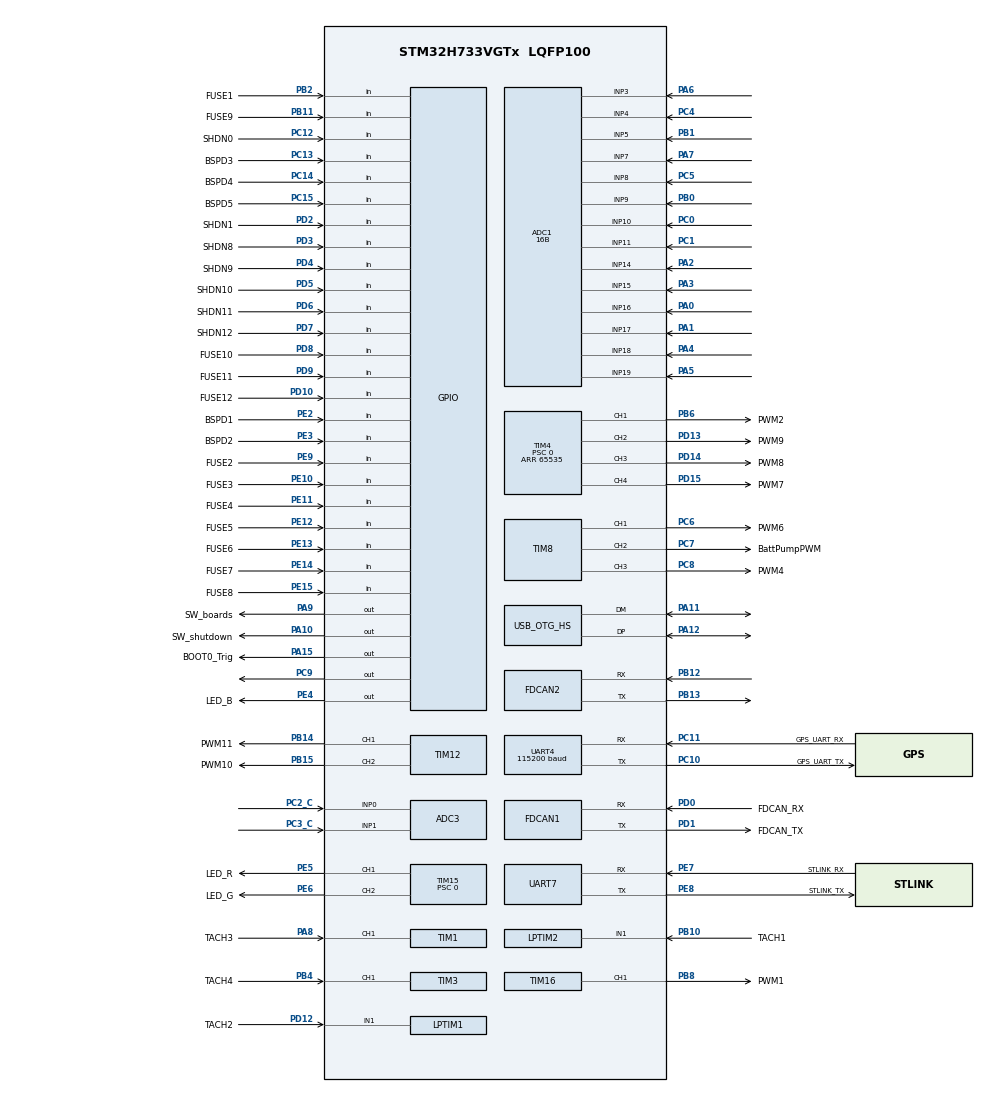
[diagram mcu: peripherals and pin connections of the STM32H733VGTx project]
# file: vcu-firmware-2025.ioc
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ADC1.Channel-1\#ChannelRegularConversion=ADC_CHANNEL_3
ADC1.Channel-10\#ChannelRegularConversion=ADC_CHANNEL_15
ADC1.Channel-11\#ChannelRegularConversion=ADC_CHANNEL_16
ADC1.Channel-12\#ChannelRegularConversion=ADC_CHANNEL_17
ADC1.Channel-13\#ChannelRegularConversion=ADC_CHANNEL_18
ADC1.Channel-14\#ChannelRegularConversion=ADC_CHANNEL_19
ADC1.Channel-2\#ChannelRegularConversion=ADC_CHANNEL_4
ADC1.Channel-3\#ChannelRegularConversion=ADC_CHANNEL_5
ADC1.Channel-4\#ChannelRegularConversion=ADC_CHANNEL_7
ADC1.Channel-5\#ChannelRegularConversion=ADC_CHANNEL_8
ADC1.Channel-6\#ChannelRegularConversion=ADC_CHANNEL_9
ADC1.Channel-7\#ChannelRegularConversion=ADC_CHANNEL_10
ADC1.Channel-8\#ChannelRegularConversion=ADC_CHANNEL_11
ADC1.Channel-9\#ChannelRegularConversion=ADC_CHANNEL_14
ADC1.ClockPrescaler=ADC_CLOCK_ASYNC_DIV64
ADC1.ContinuousConvMode=ENABLE
ADC1.ConversionDataManagement=ADC_CONVERSIONDATA_DMA_CIRCULAR
ADC1.EOCSelection=ADC_EOC_SEQ_CONV
ADC1.EnableRegularConversion=ENABLE
ADC1.NbrOfConversion=14
ADC1.NbrOfConversionFlag=1
ADC1.OffsetNumber-1\#ChannelRegularConversion=ADC_OFFSET_NONE
ADC1.OffsetNumber-10\#ChannelRegularConversion=ADC_OFFSET_NONE
ADC1.OffsetNumber-11\#ChannelRegularConversion=ADC_OFFSET_NONE
ADC1.OffsetNumber-12\#ChannelRegularConversion=ADC_OFFSET_NONE
ADC1.OffsetNumber-13\#ChannelRegularConversion=ADC_OFFSET_NONE
ADC1.OffsetNumber-14\#ChannelRegularConversion=ADC_OFFSET_NONE
ADC1.OffsetNumber-2\#ChannelRegularConversion=ADC_OFFSET_NONE
ADC1.OffsetNumber-3\#ChannelRegularConversion=ADC_OFFSET_NONE
ADC1.OffsetNumber-4\#ChannelRegularConversion=ADC_OFFSET_NONE
ADC1.OffsetNumber-5\#ChannelRegularConversion=ADC_OFFSET_NONE
ADC1.OffsetNumber-6\#ChannelRegularConversion=ADC_OFFSET_NONE
ADC1.OffsetNumber-7\#ChannelRegularConversion=ADC_OFFSET_NONE
ADC1.OffsetNumber-8\#ChannelRegularConversion=ADC_OFFSET_NONE
ADC1.OffsetNumber-9\#ChannelRegularConversion=ADC_OFFSET_NONE
ADC1.OffsetSignedSaturation-1\#ChannelRegularConversion=DISABLE
ADC1.OffsetSignedSaturation-10\#ChannelRegularConversion=DISABLE
ADC1.OffsetSignedSaturation-11\#ChannelRegularConversion=DISABLE
ADC1.OffsetSignedSaturation-12\#ChannelRegularConversion=DISABLE
ADC1.OffsetSignedSaturation-13\#ChannelRegularConversion=DISABLE
ADC1.OffsetSignedSaturation-14\#ChannelRegularConversion=DISABLE
ADC1.OffsetSignedSaturation-2\#ChannelRegularConversion=DISABLE
ADC1.OffsetSignedSaturation-3\#ChannelRegularConversion=DISABLE
ADC1.OffsetSignedSaturation-4\#ChannelRegularConversion=DISABLE
ADC1.OffsetSignedSaturation-5\#ChannelRegularConversion=DISABLE
ADC1.OffsetSignedSaturation-6\#ChannelRegularConversion=DISABLE
ADC1.OffsetSignedSaturation-7\#ChannelRegularConversion=DISABLE
ADC1.OffsetSignedSaturation-8\#ChannelRegularConversion=DISABLE
ADC1.OffsetSignedSaturation-9\#ChannelRegularConversion=DISABLE
ADC1.OversamplingMode=ENABLE
ADC1.Rank-1\#ChannelRegularConversion=1
ADC1.Rank-10\#ChannelRegularConversion=10
ADC1.Rank-11\#ChannelRegularConversion=11
ADC1.Rank-12\#ChannelRegularConversion=12
ADC1.Rank-13\#ChannelRegularConversion=13
ADC1.Rank-14\#ChannelRegularConversion=14
ADC1.Rank-2\#ChannelRegularConversion=2
ADC1.Rank-3\#ChannelRegularConversion=3
ADC1.Rank-4\#ChannelRegularConversion=4
ADC1.Rank-5\#ChannelRegularConversion=5
ADC1.Rank-6\#ChannelRegularConversion=6
ADC1.Rank-7\#ChannelRegularConversion=7
ADC1.Rank-8\#ChannelRegularConversion=8
ADC1.Rank-9\#ChannelRegularConversion=9
ADC1.Ratio=16
ADC1.Resolution=ADC_RESOLUTION_16B
ADC1.RightBitShift=ADC_RIGHTBITSHIFT_4
ADC1.SamplingTime-1\#ChannelRegularConversion=ADC_SAMPLETIME_1CYCLE_5
ADC1.SamplingTime-10\#ChannelRegularConversion=ADC_SAMPLETIME_1CYCLE_5
ADC1.SamplingTime-11\#ChannelRegularConversion=ADC_SAMPLETIME_1CYCLE_5
ADC1.SamplingTime-12\#ChannelRegularConversion=ADC_SAMPLETIME_1CYCLE_5
ADC1.SamplingTime-13\#ChannelRegularConversion=ADC_SAMPLETIME_1CYCLE_5
ADC1.SamplingTime-14\#ChannelRegularConversion=ADC_SAMPLETIME_1CYCLE_5
ADC1.SamplingTime-2\#ChannelRegularConversion=ADC_SAMPLETIME_1CYCLE_5
ADC1.SamplingTime-3\#ChannelRegularConversion=ADC_SAMPLETIME_1CYCLE_5
ADC1.SamplingTime-4\#ChannelRegularConversion=ADC_SAMPLETIME_1CYCLE_5
ADC1.SamplingTime-5\#ChannelRegularConversion=ADC_SAMPLETIME_1CYCLE_5
ADC1.SamplingTime-6\#ChannelRegularConversion=ADC_SAMPLETIME_1CYCLE_5
ADC1.SamplingTime-7\#ChannelRegularConversion=ADC_SAMPLETIME_1CYCLE_5
ADC1.SamplingTime-8\#ChannelRegularConversion=ADC_SAMPLETIME_1CYCLE_5
ADC1.SamplingTime-9\#ChannelRegularConversion=ADC_SAMPLETIME_1CYCLE_5
ADC1.master=1
ADC3.Channel-1\#ChannelRegularConversion=ADC_CHANNEL_0
ADC3.Channel-2\#ChannelRegularConversion=ADC_CHANNEL_1
ADC3.ClockPrescaler=ADC_CLOCK_ASYNC_DIV64
ADC3.ContinuousConvMode=ENABLE
ADC3.ConversionDataManagement=ADC_CONVERSIONDATA_DMA_CIRCULAR
ADC3.DMAContinuousRequests=DISABLE
ADC3.EOCSelection=ADC_EOC_SEQ_CONV
ADC3.NbrOfConversion=2
ADC3.NbrOfConversionFlag=1
ADC3.OffsetNumber-1\#ChannelRegularConversion=ADC_OFFSET_NONE
ADC3.OffsetNumber-2\#ChannelRegularConversion=ADC_OFFSET_NONE
ADC3.OffsetSign-1\#ChannelRegularConversion=ADC3_OFFSET_SIGN_NEGATIVE
ADC3.OffsetSign-2\#ChannelRegularConversion=ADC3_OFFSET_SIGN_NEGATIVE
ADC3.Rank-1\#ChannelRegularConversion=1
ADC3.Rank-2\#ChannelRegularConversion=2
ADC3.ResolutionADC3=ADC_RESOLUTION_8B
ADC3.SamplingTime-1\#ChannelRegularConversion=ADC3_SAMPLETIME_2CYCLES_5
ADC3.SamplingTime-2\#ChannelRegularConversion=ADC3_SAMPLETIME_2CYCLES_5
CORTEX_M7.default_mode_Activation=1
Dma.ADC1.0.Direction=DMA_PERIPH_TO_MEMORY
Dma.ADC1.0.EventEnable=DISABLE
Dma.ADC1.0.FIFOMode=DMA_FIFOMODE_DISABLE
Dma.ADC1.0.Instance=DMA1_Stream2
Dma.ADC1.0.MemDataAlignment=DMA_MDATAALIGN_HALFWORD
Dma.ADC1.0.MemInc=DMA_MINC_ENABLE
Dma.ADC1.0.Mode=DMA_CIRCULAR
Dma.ADC1.0.PeriphDataAlignment=DMA_PDATAALIGN_HALFWORD
Dma.ADC1.0.PeriphInc=DMA_PINC_DISABLE
Dma.ADC1.0.Polarity=HAL_DMAMUX_REQ_GEN_RISING
Dma.ADC1.0.Priority=DMA_PRIORITY_LOW
Dma.ADC1.0.RequestNumber=1
Dma.ADC1.0.SignalID=NONE
Dma.ADC1.0.SyncEnable=DISABLE
Dma.ADC1.0.SyncPolarity=HAL_DMAMUX_SYNC_NO_EVENT
Dma.ADC1.0.SyncRequestNumber=1
Dma.ADC1.0.SyncSignalID=NONE
Dma.ADC3.1.Direction=DMA_PERIPH_TO_MEMORY
Dma.ADC3.1.EventEnable=DISABLE
Dma.ADC3.1.FIFOMode=DMA_FIFOMODE_DISABLE
Dma.ADC3.1.Instance=DMA1_Stream1
Dma.ADC3.1.MemDataAlignment=DMA_MDATAALIGN_BYTE
Dma.ADC3.1.MemInc=DMA_MINC_ENABLE
Dma.ADC3.1.Mode=DMA_CIRCULAR
Dma.ADC3.1.PeriphDataAlignment=DMA_PDATAALIGN_BYTE
Dma.ADC3.1.PeriphInc=DMA_PINC_DISABLE
Dma.ADC3.1.Polarity=HAL_DMAMUX_REQ_GEN_RISING
Dma.ADC3.1.Priority=DMA_PRIORITY_HIGH
Dma.ADC3.1.RequestNumber=1
Dma.ADC3.1.SignalID=NONE
Dma.ADC3.1.SyncEnable=DISABLE
Dma.ADC3.1.SyncPolarity=HAL_DMAMUX_SYNC_NO_EVENT
Dma.ADC3.1.SyncRequestNumber=1
Dma.ADC3.1.SyncSignalID=NONE
Dma.Request0=ADC1
Dma.Request1=ADC3
Dma.Request2=UART4_RX
Dma.UART4_RX.2.Direction=DMA_PERIPH_TO_MEMORY
Dma.UART4_RX.2.EventEnable=DISABLE
Dma.UART4_RX.2.FIFOMode=DMA_FIFOMODE_DISABLE
Dma.UART4_RX.2.Instance=DMA2_Stream0
Dma.UART4_RX.2.MemDataAlignment=DMA_MDATAALIGN_BYTE
Dma.UART4_RX.2.MemInc=DMA_MINC_ENABLE
Dma.UART4_RX.2.Mode=DMA_CIRCULAR
Dma.UART4_RX.2.PeriphDataAlignment=DMA_PDATAALIGN_BYTE
Dma.UART4_RX.2.PeriphInc=DMA_PINC_DISABLE
Dma.UART4_RX.2.Polarity=HAL_DMAMUX_REQ_GEN_RISING
Dma.UART4_RX.2.Priority=DMA_PRIORITY_HIGH
Dma.UART4_RX.2.RequestNumber=1
Dma.UART4_RX.2.SignalID=NONE
Dma.UART4_RX.2.SyncEnable=DISABLE
Dma.UART4_RX.2.SyncPolarity=HAL_DMAMUX_SYNC_NO_EVENT
Dma.UART4_RX.2.SyncRequestNumber=1
Dma.UART4_RX.2.SyncSignalID=NONE
FDCAN1.CalculateBaudRateNominal=1000000
FDCAN1.CalculateTimeBitNominal=1000
FDCAN1.CalculateTimeQuantumNominal=100.0
FDCAN1.NominalPrescaler=1
FDCAN1.NominalTimeSeg1=7
FDCAN1.RxFifo0ElmtsNbr=32
FDCAN1.RxFifo1ElmtsNbr=32
FDCAN1.TxFifoQueueElmtsNbr=32
FDCAN2.CalculateBaudRateNominal=500000
FDCAN2.CalculateTimeBitNominal=2000
FDCAN2.CalculateTimeQuantumNominal=400.0
FDCAN2.ClockCalibrationCCU=DISABLE
FDCAN2.NominalPrescaler=4
Mcu.Family=STM32H7
Mcu.Name=STM32H733VGTx
Mcu.Package=LQFP100
NVIC.DMA1_Stream1_IRQn=true\:0\:0\:false\:false\:true\:false\:true\:true
NVIC.DMA1_Stream2_IRQn=true\:0\:0\:false\:false\:true\:false\:true\:true
NVIC.DMA2_Stream0_IRQn=true\:0\:0\:false\:false\:true\:false\:true\:true
NVIC.OTG_HS_IRQn=true\:0\:0\:false\:false\:true\:false\:true\:true
NVIC.PriorityGroup=NVIC_PRIORITYGROUP_4
PA0.Mode=IN16-Single-Ended
PA0.Signal=ADC1_INP16
PA1.Mode=IN17-Single-Ended
PA1.Signal=ADC1_INP17
PA10.GPIO_Label=SW_shutdown
PA10.Signal=GPIO_Output
PA11.Mode=Device_Only_FS
PA11.Signal=USB_OTG_HS_DM
PA12.Mode=Device_Only_FS
PA12.Signal=USB_OTG_HS_DP
PA13(JTMS/SWDIO).Mode=Trace_Asynchronous_SW
PA13(JTMS/SWDIO).Signal=DEBUG_JTMS-SWDIO
PA14(JTCK/SWCLK).Mode=Trace_Asynchronous_SW
PA14(JTCK/SWCLK).Signal=DEBUG_JTCK-SWCLK
PA15(JTDI).GPIO_Label=BOOT0_Trig
PA15(JTDI).GPIO_PuPd=GPIO_PULLDOWN
PA15(JTDI).PinState=GPIO_PIN_RESET
PA15(JTDI).Signal=GPIO_Output
PA2.Signal=ADCx_INP14
PA3.Signal=ADCx_INP15
PA4.Signal=ADCx_INP18
PA5.Signal=ADCx_INP19
PA6.Signal=ADCx_INP3
PA7.Signal=ADCx_INP7
PA8.GPIO_Label=TACH3
PA8.Signal=S_TIM1_CH1
PA9.GPIO_Label=SW_boards
PA9.Signal=GPIO_Output
PB0.Signal=ADCx_INP9
PB1.Signal=ADCx_INP5
PB10.GPIO_Label=TACH1
PB10.Mode=Counts_external_clock_standalone_1X_occur1
PB10.Signal=LPTIM2_IN1
PB11.GPIO_Label=FUSE9
PB11.Signal=GPIO_Input
PB12.Mode=FDCAN_Activate
PB12.Signal=FDCAN2_RX
PB13.Mode=FDCAN_Activate
PB13.Signal=FDCAN2_TX
PB14.GPIO_Label=PWM11
PB14.Signal=S_TIM12_CH1
PB15.GPIO_Label=PWM10
PB15.Signal=S_TIM12_CH2
PB2.GPIO_Label=FUSE1
PB2.Signal=GPIO_Input
PB3(JTDO/TRACESWO).Mode=Trace_Asynchronous_SW
PB3(JTDO/TRACESWO).Signal=DEBUG_JTDO-SWO
PB4(NJTRST).GPIO_Label=TACH4
PB4(NJTRST).Signal=S_TIM3_CH1
PB6.GPIO_Label=PWM2
PB6.Signal=S_TIM4_CH1
PB8.GPIO_FM8=SYSCFG_PMCR_I2C_PB8_FMP
PB8.GPIO_Label=PWM1
PB8.GPIO_Speed=GPIO_SPEED_FREQ_VERY_HIGH
PB8.Signal=S_TIM16_CH1
PC0.Signal=ADCx_INP10
PC1.Signal=ADCx_INP11
PC10.GPIO_Label=GPS_UART_TX
PC10.Mode=Asynchronous
PC10.Signal=UART4_TX
PC11.GPIO_Label=GPS_UART_RX
PC11.Mode=Asynchronous
PC11.Signal=UART4_RX
PC12.GPIO_Label=SHDN0
PC12.Signal=GPIO_Input
PC13.GPIO_Label=BSPD3
PC13.GPIO_PuPd=GPIO_PULLDOWN
PC13.Signal=GPIO_Input
PC14-OSC32_IN.GPIO_Label=BSPD4
PC14-OSC32_IN.GPIO_PuPd=GPIO_PULLDOWN
PC14-OSC32_IN.Signal=GPIO_Input
PC15-OSC32_OUT.GPIO_Label=BSPD5
PC15-OSC32_OUT.GPIO_PuPd=GPIO_PULLDOWN
PC15-OSC32_OUT.Signal=GPIO_Input
PC2_C.Mode=IN0-Single-Ended
PC2_C.Signal=ADC3_INP0
PC3_C.Mode=IN1-Single-Ended
PC3_C.Signal=ADC3_INP1
PC4.Signal=ADCx_INP4
PC5.Signal=ADCx_INP8
PC6.GPIO_Label=PWM6
PC6.Signal=S_TIM8_CH1
PC7.GPIO_Label=BattPumpPWM
PC7.Signal=S_TIM8_CH2
PC8.GPIO_Label=PWM4
PC8.Signal=S_TIM8_CH3
PC9.Signal=GPIO_Output
PD0.GPIO_Label=FDCAN_RX
PD0.GPIO_Speed=GPIO_SPEED_FREQ_HIGH
PD0.Mode=FDCAN_Activate
PD0.Signal=FDCAN1_RX
PD1.GPIO_Label=FDCAN_TX
PD1.GPIO_Speed=GPIO_SPEED_FREQ_HIGH
PD1.Mode=FDCAN_Activate
PD1.Signal=FDCAN1_TX
PD10.GPIO_Label=FUSE12
PD10.Signal=GPIO_Input
PD12.GPIO_Label=TACH2
PD12.Mode=Counts_external_clock_standalone_1X_occur1
PD12.Signal=LPTIM1_IN1
PD13.GPIO_Label=PWM9
PD13.Signal=S_TIM4_CH2
PD14.GPIO_Label=PWM8
PD14.Signal=S_TIM4_CH3
PD15.GPIO_Label=PWM7
PD15.Signal=S_TIM4_CH4
PD2.GPIO_Label=SHDN1
PD2.Signal=GPIO_Input
PD3.GPIO_Label=SHDN8
PD3.Signal=GPIO_Input
PD4.GPIO_Label=SHDN9
PD4.Signal=GPIO_Input
PD5.GPIO_Label=SHDN10
PD5.Signal=GPIO_Input
PD6.GPIO_Label=SHDN11
PD6.Signal=GPIO_Input
PD7.GPIO_Label=SHDN12
PD7.Signal=GPIO_Input
PD8.GPIO_Label=FUSE10
PD8.Signal=GPIO_Input
PD9.GPIO_Label=FUSE11
PD9.Signal=GPIO_Input
PE10.GPIO_Label=FUSE3
PE10.Signal=GPIO_Input
PE11.GPIO_Label=FUSE4
PE11.Signal=GPIO_Input
PE12.GPIO_Label=FUSE5
PE12.Signal=GPIO_Input
PE13.GPIO_Label=FUSE6
PE13.Signal=GPIO_Input
PE14.GPIO_Label=FUSE7
PE14.Signal=GPIO_Input
PE15.GPIO_Label=FUSE8
PE15.Signal=GPIO_Input
PE2.GPIO_Label=BSPD1
PE2.GPIO_PuPd=GPIO_PULLDOWN
PE2.Signal=GPIO_Input
PE3.GPIO_Label=BSPD2
PE3.GPIO_PuPd=GPIO_PULLDOWN
PE3.Signal=GPIO_Input
PE4.GPIO_Label=LED_B
PE4.GPIO_PuPd=GPIO_NOPULL
PE4.Signal=GPIO_Output
PE5.GPIO_Label=LED_R
PE5.GPIO_ModeDefaultPP=GPIO_MODE_AF_OD
PE5.GPIO_PuPd=GPIO_NOPULL
PE5.GPIO_Speed=GPIO_SPEED_FREQ_VERY_HIGH
PE5.Signal=S_TIM15_CH1
PE6.GPIO_Label=LED_G
PE6.GPIO_ModeDefaultPP=GPIO_MODE_AF_OD
PE6.GPIO_Speed=GPIO_SPEED_FREQ_VERY_HIGH
PE6.Signal=S_TIM15_CH2
PE7.GPIO_Label=STLINK_RX
PE7.Mode=Asynchronous
PE7.Signal=UART7_RX
PE8.GPIO_Label=STLINK_TX
PE8.Mode=Asynchronous
PE8.Signal=UART7_TX
PE9.GPIO_Label=FUSE2
PE9.Signal=GPIO_Input
PH0-OSC_IN.Mode=HSE-External-Oscillator
PH0-OSC_IN.Signal=RCC_OSC_IN
PH1-OSC_OUT.Mode=HSE-External-Oscillator
PH1-OSC_OUT.Signal=RCC_OSC_OUT
ProjectManager.HeapSize=0x200
ProjectManager.StackSize=0x400
ProjectManager.TargetToolchain=STM32CubeIDE
RCC.ADCFreq_Value=128000000
RCC.APB1Freq_Value=137500000
RCC.APB2Freq_Value=137500000
RCC.APB3Freq_Value=137500000
RCC.APB4Freq_Value=137500000
RCC.CortexFreq_Value=550000000
RCC.D1PPRE=RCC_APB3_DIV2
RCC.D2PPRE1=RCC_APB1_DIV2
RCC.D2PPRE2=RCC_APB2_DIV2
RCC.D3PPRE=RCC_APB4_DIV2
RCC.DIVM1=8
RCC.DIVM2=16
RCC.DIVM3=16
RCC.DIVN1=275
RCC.DIVN2=256
RCC.DIVN3=192
RCC.DIVP1=1
RCC.DIVQ1=55
RCC.DIVQ2=4
RCC.DIVQ3=4
RCC.DIVR1=55
RCC.HCLKFreq_Value=275000000
RCC.HPRE=RCC_HCLK_DIV2
RCC.HSE_VALUE=16000000
RCC.PLLSourceVirtual=RCC_PLLSOURCE_HSE
RCC.SYSCLKFreq_VALUE=550000000
RCC.SYSCLKSource=RCC_SYSCLKSOURCE_PLLCLK
RCC.USBCLockSelection=RCC_USBCLKSOURCE_PLL3
RCC.USBFreq_Value=48000000
SH.ADCx_INP10.0=ADC1_INP10,IN10-Single-Ended
SH.ADCx_INP11.0=ADC1_INP11,IN11-Single-Ended
SH.ADCx_INP14.0=ADC1_INP14,IN14-Single-Ended
SH.ADCx_INP15.0=ADC1_INP15,IN15-Single-Ended
SH.ADCx_INP18.0=ADC1_INP18,IN18-Single-Ended
SH.ADCx_INP19.0=ADC1_INP19,IN19-Single-Ended
SH.ADCx_INP3.0=ADC1_INP3,IN3-Single-Ended
SH.ADCx_INP4.0=ADC1_INP4,IN4-Single-Ended
SH.ADCx_INP5.0=ADC1_INP5,IN5-Single-Ended
SH.ADCx_INP7.0=ADC1_INP7,IN7-Single-Ended
SH.ADCx_INP8.0=ADC1_INP8,IN8-Single-Ended
SH.ADCx_INP9.0=ADC1_INP9,IN9-Single-Ended
SH.S_TIM12_CH1.0=TIM12_CH1,PWM Generation1 CH1
SH.S_TIM12_CH2.0=TIM12_CH2,PWM Generation2 CH2
SH.S_TIM15_CH1.0=TIM15_CH1,PWM Generation1 CH1
SH.S_TIM15_CH2.0=TIM15_CH2,PWM Generation2 CH2
SH.S_TIM16_CH1.0=TIM16_CH1,PWM Generation1 CH1
SH.S_TIM1_CH1.0=TIM1_CH1,TriggerSource_TI1ED
SH.S_TIM3_CH1.0=TIM3_CH1,TriggerSource_TI1ED
SH.S_TIM4_CH1.0=TIM4_CH1,PWM Generation1 CH1
SH.S_TIM4_CH2.0=TIM4_CH2,PWM Generation2 CH2
SH.S_TIM4_CH3.0=TIM4_CH3,PWM Generation3 CH3
SH.S_TIM4_CH4.0=TIM4_CH4,PWM Generation4 CH4
SH.S_TIM8_CH1.0=TIM8_CH1,PWM Generation1 CH1
SH.S_TIM8_CH2.0=TIM8_CH2,PWM Generation2 CH2
SH.S_TIM8_CH3.0=TIM8_CH3,PWM Generation3 CH3
TIM12.Channel-PWM\ Generation1\ CH1=TIM_CHANNEL_1
TIM12.Channel-PWM\ Generation2\ CH2=TIM_CHANNEL_2
TIM15.AutoReloadPreload=TIM_AUTORELOAD_PRELOAD_ENABLE
TIM15.Channel-PWM\ Generation1\ CH1=TIM_CHANNEL_1
TIM15.Channel-PWM\ Generation2\ CH2=TIM_CHANNEL_2
TIM15.OCPolarity_1=TIM_OCPOLARITY_LOW
TIM15.OCPolarity_2=TIM_OCPOLARITY_LOW
TIM15.Period=1000
TIM15.Prescaler=0
TIM16.AutoReloadPreload=TIM_AUTORELOAD_PRELOAD_ENABLE
TIM16.Channel=TIM_CHANNEL_1
TIM16.OCFastMode_PWM=TIM_OCFAST_ENABLE
TIM16.Period=65535
TIM16.Prescaler=2
TIM16.Pulse=2500
TIM4.Channel-PWM\ Generation1\ CH1=TIM_CHANNEL_1
TIM4.Channel-PWM\ Generation2\ CH2=TIM_CHANNEL_2
TIM4.Channel-PWM\ Generation3\ CH3=TIM_CHANNEL_3
TIM4.Channel-PWM\ Generation4\ CH4=TIM_CHANNEL_4
TIM4.OCFastMode_PWM-PWM\ Generation1\ CH1=TIM_OCFAST_ENABLE
TIM4.OCFastMode_PWM-PWM\ Generation2\ CH2=TIM_OCFAST_ENABLE
TIM4.OCFastMode_PWM-PWM\ Generation4\ CH4=TIM_OCFAST_ENABLE
TIM4.Period=65535
TIM4.Prescaler=0
TIM8.Channel-PWM\ Generation1\ CH1=TIM_CHANNEL_1
TIM8.Channel-PWM\ Generation2\ CH2=TIM_CHANNEL_2
TIM8.Channel-PWM\ Generation3\ CH3=TIM_CHANNEL_3
TIM8.OCFastMode_PWM-PWM\ Generation2\ CH2=TIM_OCFAST_ENABLE
UART4.BaudRate=115200
USB_DEVICE.CLASS_NAME_HS=CDC
USB_DEVICE.MANUFACTURER_STRING=Longhorn Racing Electric
USB_DEVICE.PRODUCT_STRING_CDC_HS=LHRe Vehicle Control Unit
USB_DEVICE.VID=1221
USB_DEVICE.VirtualMode=Cdc
USB_DEVICE.VirtualModeHS=Cdc_HS
USB_OTG_HS.VirtualMode-Device_Only_FS=Device_Only_FS
VP_MEMORYMAP_VS_MEMORYMAP.Mode=CurAppReg
VP_TIM12_VS_ClockSourceINT.Mode=Internal
VP_TIM15_VS_ClockSourceINT.Mode=Internal
VP_TIM16_VS_ClockSourceINT.Mode=Enable_Timer
VP_TIM1_VS_ControllerModeClock.Mode=Clock Mode
VP_TIM3_VS_ControllerModeClock.Mode=Clock Mode
VP_TIM4_VS_ClockSourceINT.Mode=Internal
VP_TIM8_VS_ClockSourceINT.Mode=Internal
VP_USB_DEVICE_VS_USB_DEVICE_CDC_HS.Mode=CDC_HS
board=custom

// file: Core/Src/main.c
/* USER CODE BEGIN Header */
/**
  ******************************************************************************
  * @file           : main.c
  * @brief          : Main program body
  ******************************************************************************
  * @attention
  *
  * Copyright (c) 2024 STMicroelectronics.
  * All rights reserved.
  *
  * This software is licensed under terms that can be found in the LICENSE file
  * in the root directory of this software component.
  * If no LICENSE file comes with this software, it is provided AS-IS.
  *
  ******************************************************************************
  */
/* USER CODE END Header */
#include "main.h"
#include "adc.h"
#include "dma.h"
#include "fdcan.h"
#include "lptim.h"
#include "memorymap.h"
#include "tim.h"
#include "usart.h"
#include "usb_device.h"
#include "gpio.h"

/* USER CODE BEGIN Includes */

#include "usb_vcp.h"
#include "pdu.h"
#include "led.h"
#include "VcuModel.h"
#include "dfu.h"
#include "bspd.h"
#include "timer.h"
#include "current_sense.h"
#include "night_can.h"
#include "inverter.h"
#include "gps.h"
#include "hvc.h"
#include "sensors.h"
/* USER CODE END Includes */

void SystemClock_Config(void);
void PeriphCommonClock_Config(void);
static void MPU_Config(void);

/* USER CODE BEGIN 0 */
bool isFinished;

void HAL_ADC_ConvCpltCallback(ADC_HandleTypeDef* hadc)
{
  isFinished = 1;
}

#define GPS_BUFFER_SIZE 256       // Size of the circular DMA buffer (power of 2 often good, but not required)
#define NMEA_MESSAGE_MAX_LEN 100  // Max expected length of a single NMEA sentence (e.g., $...*CS\r\n)

uint8_t GPS_BUFFER[GPS_BUFFER_SIZE];

// Pointer (index) to the next byte to be processed by the application
// Needs to be volatile as it's used in main loop context potentially interrupted by other things,
// though the primary interaction is with DMA state which is checked explicitly. Safety first.
volatile uint16_t app_read_ptr = 0;

// Buffer to assemble the current NMEA message being processed
uint8_t current_nmea_message[NMEA_MESSAGE_MAX_LEN];
uint16_t current_nmea_idx = 0;
bool accumulating_nmea = false; // State flag: are we currently inside a $... message?

// External declaration for the DMA handle associated with UART4 RX
// Make sure this matches the handle name generated by CubeMX (e.g., hdma_uart4_rx)
extern DMA_HandleTypeDef hdma_uart4_rx;

/**
  * @brief Processes the data received in the circular GPS DMA buffer.
  * Scans for NMEA messages ($ to \n) between the application read pointer
  * and the current DMA write pointer.
  * @retval None
  */
void process_gps_dma_buffer(void)
{
  // Get the current position of the DMA write pointer.
  // CNDTR counts *down* from the buffer size. The number of bytes written
  // since the last wrap-around = buffer_size - CNDTR.
  // The write pointer index is this value modulo buffer_size.
  uint16_t dma_write_ptr = (GPS_BUFFER_SIZE - __HAL_DMA_GET_COUNTER(&hdma_uart4_rx)) % GPS_BUFFER_SIZE;

  // Process data byte by byte from the app's read pointer up to the DMA's write pointer
  while (app_read_ptr != dma_write_ptr)
  {
    // Get the byte pointed to by the application read pointer
    uint8_t current_byte = GPS_BUFFER[app_read_ptr];

    // --- NMEA Sentence Detection Logic ---
    if (current_byte == '$')
    {
      // Start of a new NMEA sentence
      memset(current_nmea_message, 0, NMEA_MESSAGE_MAX_LEN); // Clear previous buffer contents
      current_nmea_message[0] = '$';
      current_nmea_idx = 1;
      accumulating_nmea = true;
    }
    else if (accumulating_nmea)
    {
      // If we have already found '$', keep accumulating characters
      if (current_nmea_idx < (NMEA_MESSAGE_MAX_LEN - 1))
      {
        // Add character to our message buffer
        current_nmea_message[current_nmea_idx++] = current_byte;
      }
      else
      {
        // Error: NMEA message too long for our buffer. Discard and reset.
        accumulating_nmea = false;
        current_nmea_idx = 0;
        // Optional: Log this overflow error
        usb_printf("ERROR: NMEA sentence overflow!\r\n");
      }

      // Check if this character terminates the message ('\n')
      // NMEA sentences typically end with \r\n, but checking for \n is usually sufficient.
      if (current_byte == '\n')
      {
        // End of sentence found
        current_nmea_message[current_nmea_idx] = '\0'; // Null-terminate the string

        // --- Message Complete ---
        // You now have a complete NMEA sentence in current_nmea_message
        // TODO: Process the complete NMEA sentence here!
        // Examples:
        //                usb_printf("GPS: %s", current_nmea_message); // Print the raw message (includes \r\n)
        // parse_nmea_sentence(current_nmea_message); // Call your parsing function
        // set_gps_data_ready_flag(); // Set a flag for another task

        // Reset state for the next message
        accumulating_nmea = false;
        current_nmea_idx = 0;
      }
    }
    // --- End NMEA Logic ---

    // Increment the application read pointer, wrapping around the buffer
    app_read_ptr = (app_read_ptr + 1) % GPS_BUFFER_SIZE;
  }
}

#define GPS_BUFFER_SIZE 256       // Size of the circular DMA buffer (power of 2 often good, but not required)
#define NMEA_MESSAGE_MAX_LEN 100  // Max expected length of a single NMEA sentence (e.g., $...*CS\r\n)

uint16_t ADC1_BUFFER[14] = {}; // 14 element 16bit ADC resolution buffer
uint8_t ADC3_BUFFER[2] = {};

// The DMA buffer - ensure it's placed in memory accessible by the DMA controller
// Use __attribute__((section(".dma_buffer"))) or similar if you have specific RAM regions.
uint8_t GPS_BUFFER[GPS_BUFFER_SIZE];

extern DMA_HandleTypeDef hdma_uart4_rx;

/* USER CODE END 0 */

int main(void)
{

  /* MPU Configuration--------------------------------------------------------*/
  MPU_Config();

  /* MCU Configuration--------------------------------------------------------*/

  /* Reset of all peripherals, Initializes the Flash interface and the Systick. */
  HAL_Init();

  /* Configure the system clock */
  SystemClock_Config();

  /* Configure the peripherals common clocks */
  PeriphCommonClock_Config();

  /* Initialize all configured peripherals */
  MX_GPIO_Init();
  MX_DMA_Init();
  MX_ADC1_Init();
  MX_ADC3_Init();
  MX_FDCAN1_Init();
  MX_FDCAN2_Init();
  MX_LPTIM1_Init();
  MX_LPTIM2_Init();
  MX_TIM1_Init();
  MX_TIM3_Init();
  MX_TIM4_Init();
  MX_TIM8_Init();
  MX_TIM12_Init();
  MX_TIM15_Init();
  MX_TIM16_Init();
  MX_UART4_Init();
  MX_USB_DEVICE_Init();
  MX_UART7_Init();
  /* USER CODE BEGIN 2 */
  PDUData pduData = {};
  HvcStatus hvcStatus = {};
  BSPDOutputs bspd = {};
  BSPDOutputs* bspdaddr = &bspd;
  SensorData sensors = {};
  InverterData inverterData = {};

  /* Initialize Structures/Subsystems */
  led_init(TIM15, &htim15, 2); // missing a channel on the vcu
  dfu_init(GPIOA, GPIO_PIN_15);
  HAL_ADC_Start_DMA(&hadc1, (uint32_t*)ADC1_BUFFER, 14);
  HAL_ADC_Start_DMA(&hadc3, (uint32_t*)ADC3_BUFFER, 2);
  lib_timer_init();

  NightCANInstance carCAN = CAN_new_instance();
  CAN_Init(&carCAN, &hfdcan1, 0, 0x7FF, 0, 0);
  pdu_init(&pduData, &carCAN);
  sensors_init(&hfdcan1, &carCAN);
  inverter_init(&carCAN);
  hvc_init(&carCAN);

  NightCANPacket buzz_pkt = CAN_create_packet(0x1A0, 100, 1);

  CAN_AddTxPacket(&carCAN, &buzz_pkt);

  VcuModelParameters params = {
    .apps = {
      .apps1VoltageMin = 1.400f, // TODO tune pedals
      .apps1VoltageMax = 2.350f,
      .apps2VoltageMin = 0.730f,
      .apps2VoltageMax = 1.160f,

      .appsMaxImplausibilityTime = 0.100f,
      .allowedPlausibilityRange = 0.10f,
      .appsDeadzoneBottomPercent = 0.05f,
      .appsDeadzoneTopPercent = 0.05f,
      .appsLowPassFilterTimeConstant = 0.02f,
    },
    .bse = {
      .bseMinAllowableVoltage = 0.08f,
      .bseMaxAllowableVoltage = 4.5f,
      .bseZeroPressureVoltage = 0.09f,
      .bseMaxPressureVoltage = 4.5f,
      .bseMaxPressure = 3000.0f,
      .bseBrakingPressure = 1.0f, // psi
      .bseMaxImplausibilityTime = 0.100f,
      .bseLowPassFilterTimeConstant = 0.0f,
    },
    .stompp = {
      .stomppAppsRecoveryThreshold = 0.05f,
      .stomppAppsCutoffThreshold = 0.25f
    },
    // .parkDrive = {
    //   .buzzerDuration = 1.0f,
    // },
    .torque = {
      .mapPedalToTorqueRequest = {
        .x0 = 0.0f,
        .x1 = 1.0f,
        .y = {},
        .xP = 1.0f,
        // .yP = 220.0f
        .yP = 15.0f // TODO for E-tech only
      }
    }
  };

  VcuModelInputs vcuModelInputs = {};
  VcuModelOutputs vcuModelOutputs = {};

  VcuModel_setParams(&params);
  /* USER CODE END 2 */

  /* Infinite loop */
  /* USER CODE BEGIN WHILE */
  led_rainbow(10 / 1000.0f);

  HAL_GPIO_WritePin(GPIOE, GPIO_PIN_4, GPIO_PIN_SET);
  HAL_LPTIM_Init(&hlptim2);

  // HAL_UART_Receive_DMA(&huart4, GPS_BUFFER, GPS_BUFFER_SIZE);

  // HAL_LPTIM_Counter_Start(&hlptim2, hlptim2.Instance->ARR);

  // __HAL_UART_CLEAR_FLAG(&huart4, UART_FLAG_ORE);
  // GPSData gpsData = {};

  // setup_gps(&gpsData, &carCAN);

  while (1)
  {
    float deltaTime = lib_timer_deltaTime();
    led_rainbow(deltaTime);

    float bse3 = ADC1_BUFFER[BSE3_IDX] * 15.1f / 10.0f * 3.3f / 65535.0f; // voltage at i/o (5v scale)

    receive_periodic();
    bspd_periodic(bspdaddr);
    pdu_periodic(&pduData);
    hvc_periodic(&hvcStatus);
    sensors_periodic(&sensors, &vcuModelInputs);
    inverter_periodic(&inverterData);

    /** ---- Inverter ---- */
    inverter_update_torque_request(vcuModelOutputs.torqueCommand);

    // vcuModelInputs.bseFVoltage = vcuModelInputs.bseRVoltage; // TODO lmao
    vcuModelInputs.bseFVoltage = bse3;
    vcuModelInputs.bseRVoltage = bse3;
    vcuModelInputs.apps1Voltage = ADC1_BUFFER[THERM_MOTOR_1_IDX] * 3.3f / 65535.0f;
    vcuModelInputs.apps2Voltage = ADC1_BUFFER[THERM_MOTOR_2_IDX] * 3.3f / 65535.0f;
    vcuModelInputs.tractiveSystemReady = (!hvcStatus.isTimedOut) && hvcStatus.energized;
    // vcuModelInputs.tractiveSystemReady = true;

    VcuModel_evaluate(&vcuModelInputs, &vcuModelOutputs, deltaTime);

    /** ---- COOLING TACHOMETERS ---- */
    // Never validated.
    // uint32_t tach = HAL_LPTIM_ReadCounter(&hlptim2);

    /** ---- GPS ---- */
    // process_gps_dma_buffer();
    // send_GPS_CAN();
    // process_nmea(current_nmea_message);

    /** ---- CAN SUBSYSTEM PERIODIC ---- */
    // Unconditionally sends ALL CAN Packets that have been marked for sending
    // IFF the time quanta reached
    // ALSO READS ALL CAN packets -- these are made available in the next main loop within the structs
    CAN_periodic(&carCAN);
    buzz_pkt.data[0] = vcuModelOutputs.buzzerEnabled;
    pduData.switches.brake_light = vcuModelOutputs.brakeLightPercent;
    // pduData.switches.brake_light = 0.5f;
   // pduData.switches.brake_light = ((lib_timer_elapsed_ms() / 200) % 2) * 0.5f;;

    if(hvcStatus.isTimedOut)
    {
      pduData.switches.green_status_light = 0.005f;
      pduData.switches.red_status_light = 0.0f;
      // pduData.switches.green_status_light = ((lib_timer_elapsed_ms() / 200) % 2) * 0.005f;
      // pduData.switches.red_status_light = ((lib_timer_elapsed_ms() / 200) % 2) * 0.005f;
    } else if (hvcStatus.bmsError || hvcStatus.imdError)
    {
      pduData.switches.green_status_light = 0.0f;
      pduData.switches.red_status_light = ((lib_timer_elapsed_ms() / 200) % 2) * 0.005f;
    } else {
      pduData.switches.green_status_light = 0.005f;
      pduData.switches.red_status_light = 0.0f;
    }

    if(vcuModelOutputs.driveStateEnabled)
    {
      pduData.switches.rad_fans = 1.0f;
      pduData.switches.cooling_pump_1 = 1.0f;
    } else
    {
      pduData.switches.rad_fans = 0.0f;
      pduData.switches.cooling_pump_1 = 0.0f;
    }

    static int x = 0;
    if ((x++) % 2000 == 0)
    {
      // steering angle
      // usb_printf("steering angle: %f", sensors.pedalBox.columnAngle);

      // inverter and resolver
      // usb_printf("angle: %fdeg\t rpm: %frpm", inverterData.electricalAngle, inverterData.motorRpm);

      // brake test
      // usb_printf("status: %d, bseF: %.2fV, bseR: %.2fV, bseF: %.2fpsi, bseR: %.2fpsi, bseAvg: %.2fpsi, pressed: %d",
      // vcuModelOutputs.bseStatus, vcuModelInputs.bseFVoltage, vcuModelInputs.bseRVoltage, vcuModelOutputs.bseFPressure, vcuModelOutputs.bseRPressure, vcuModelOutputs.bseAvgPressure, vcuModelOutputs.isDriverBraking);

      // apps
      // usb_printf("status: %d, apps1: %.3fV, apps2: %.3fV, apps1: %.2f%%, apps2: %.2f%%, apps: %.2f%%",
      // vcuModelOutputs.appsStatus, vcuModelInputs.apps1Voltage, vcuModelInputs.apps2Voltage, vcuModelOutputs.apps1Percent*100, vcuModelOutputs.apps2Percent*100, vcuModelOutputs.appsPercent*100);

      // park drive state machine
      // usb_printf("apps: %.2f, appsStompp : %.2f, braking: %d, switch: %d, drive: %d, buzz: %d", vcuModelOutputs.appsPercent, vcuModelOutputs.appsPercentStompp, vcuModelOutputs.isDriverBraking, vcuModelInputs.driveSwitchEnabled, vcuModelOutputs.driveStateEnabled, vcuModelOutputs.buzzerEnabled);

      // torque command
      // usb_printf("state: %d, torque: %.2f, enable: %d", vcuModelOutputs.driveStateEnabled, vcuModelOutputs.torqueCommand, vcuModelOutputs.enableInverter);

      // ride heights
      // usb_printf("ride heights FL=%.1fmm, FR=%.1fmm, RL=%.1fmm, RR=%.1fmm", sensors.fl.rideHeight, sensors.fr.rideHeight, sensors.rl.rideHeight, sensors.rr.rideHeight);

      // BSPD
      float hallEffectVoltage = ((float)ADC1_BUFFER[HALL_EFFECT_IDX]) * 15.1f / 10.0f * 3.3f / 65535.0f;
      float bse3Voltage = ((float)ADC1_BUFFER[BSE3_IDX]) * 15.1f / 10.0f * 3.3f / 65535.0f;
      usb_printf("hall effect: %.3fV, bse3: %.3fV", hallEffectVoltage, bse3Voltage);

      // thermistors
      // float vt1 = ((float)ADC1_BUFFER[THERM_MOTOR_1_IDX]) * 3.3f / 65535.0f;
      // float vt2 = ((float)ADC1_BUFFER[THERM_MOTOR_2_IDX]) * 3.3f / 65535.0f;
      // float vt3 = ((float)ADC1_BUFFER[THERM_MOTOR_3_IDX]) * 3.3f / 65535.0f;
      // usb_printf("t1: %.3fV, t2: %.3fV, t3: %.3fV", vt1, vt2, vt3);

      // hvc
      usb_printf("hvc status: %d bms, %d imd, %.1f max temp", hvcStatus.bmsError, hvcStatus.imdError, hvcStatus.batteryMaxTemp);

    }

    /* USER CODE END WHILE */

  }
}

void SystemClock_Config(void)
{
  RCC_OscInitTypeDef RCC_OscInitStruct = {0};
  RCC_ClkInitTypeDef RCC_ClkInitStruct = {0};

  /** Supply configuration update enable
  */
  HAL_PWREx_ConfigSupply(PWR_LDO_SUPPLY);

  /** Configure the main internal regulator output voltage
  */
  __HAL_PWR_VOLTAGESCALING_CONFIG(PWR_REGULATOR_VOLTAGE_SCALE0);

  while(!__HAL_PWR_GET_FLAG(PWR_FLAG_VOSRDY)) {}

  /** Initializes the RCC Oscillators according to the specified parameters
  * in the RCC_OscInitTypeDef structure.
  */
  RCC_OscInitStruct.OscillatorType = RCC_OSCILLATORTYPE_HSE;
  RCC_OscInitStruct.HSEState = RCC_HSE_ON;
  RCC_OscInitStruct.PLL.PLLState = RCC_PLL_ON;
  RCC_OscInitStruct.PLL.PLLSource = RCC_PLLSOURCE_HSE;
  RCC_OscInitStruct.PLL.PLLM = 8;
  RCC_OscInitStruct.PLL.PLLN = 275;
  RCC_OscInitStruct.PLL.PLLP = 1;
  RCC_OscInitStruct.PLL.PLLQ = 55;
  RCC_OscInitStruct.PLL.PLLR = 55;
  RCC_OscInitStruct.PLL.PLLRGE = RCC_PLL1VCIRANGE_1;
  RCC_OscInitStruct.PLL.PLLVCOSEL = RCC_PLL1VCOWIDE;
  RCC_OscInitStruct.PLL.PLLFRACN = 0;
  if (HAL_RCC_OscConfig(&RCC_OscInitStruct) != HAL_OK)
  {
    Error_Handler();
  }

  /** Initializes the CPU, AHB and APB buses clocks
  */
  RCC_ClkInitStruct.ClockType = RCC_CLOCKTYPE_HCLK|RCC_CLOCKTYPE_SYSCLK
                              |RCC_CLOCKTYPE_PCLK1|RCC_CLOCKTYPE_PCLK2
                              |RCC_CLOCKTYPE_D3PCLK1|RCC_CLOCKTYPE_D1PCLK1;
  RCC_ClkInitStruct.SYSCLKSource = RCC_SYSCLKSOURCE_PLLCLK;
  RCC_ClkInitStruct.SYSCLKDivider = RCC_SYSCLK_DIV1;
  RCC_ClkInitStruct.AHBCLKDivider = RCC_HCLK_DIV2;
  RCC_ClkInitStruct.APB3CLKDivider = RCC_APB3_DIV2;
  RCC_ClkInitStruct.APB1CLKDivider = RCC_APB1_DIV2;
  RCC_ClkInitStruct.APB2CLKDivider = RCC_APB2_DIV2;
  RCC_ClkInitStruct.APB4CLKDivider = RCC_APB4_DIV2;

  if (HAL_RCC_ClockConfig(&RCC_ClkInitStruct, FLASH_LATENCY_3) != HAL_OK)
  {
    Error_Handler();
  }
}

void PeriphCommonClock_Config(void)
{
  RCC_PeriphCLKInitTypeDef PeriphClkInitStruct = {0};

  /** Initializes the peripherals clock
  */
  PeriphClkInitStruct.PeriphClockSelection = RCC_PERIPHCLK_ADC;
  PeriphClkInitStruct.PLL2.PLL2M = 16;
  PeriphClkInitStruct.PLL2.PLL2N = 256;
  PeriphClkInitStruct.PLL2.PLL2P = 2;
  PeriphClkInitStruct.PLL2.PLL2Q = 4;
  PeriphClkInitStruct.PLL2.PLL2R = 2;
  PeriphClkInitStruct.PLL2.PLL2RGE = RCC_PLL2VCIRANGE_0;
  PeriphClkInitStruct.PLL2.PLL2VCOSEL = RCC_PLL2VCOMEDIUM;
  PeriphClkInitStruct.PLL2.PLL2FRACN = 0;
  PeriphClkInitStruct.AdcClockSelection = RCC_ADCCLKSOURCE_PLL2;
  if (HAL_RCCEx_PeriphCLKConfig(&PeriphClkInitStruct) != HAL_OK)
  {
    Error_Handler();
  }
}

 /* MPU Configuration */

void MPU_Config(void)
{
  MPU_Region_InitTypeDef MPU_InitStruct = {0};

  /* Disables the MPU */
  HAL_MPU_Disable();

  /** Initializes and configures the Region and the memory to be protected
  */
  MPU_InitStruct.Enable = MPU_REGION_ENABLE;
  MPU_InitStruct.Number = MPU_REGION_NUMBER0;
  MPU_InitStruct.BaseAddress = 0x0;
  MPU_InitStruct.Size = MPU_REGION_SIZE_4GB;
  MPU_InitStruct.SubRegionDisable = 0x87;
  MPU_InitStruct.TypeExtField = MPU_TEX_LEVEL0;
  MPU_InitStruct.AccessPermission = MPU_REGION_NO_ACCESS;
  MPU_InitStruct.DisableExec = MPU_INSTRUCTION_ACCESS_DISABLE;
  MPU_InitStruct.IsShareable = MPU_ACCESS_SHAREABLE;
  MPU_InitStruct.IsCacheable = MPU_ACCESS_NOT_CACHEABLE;
  MPU_InitStruct.IsBufferable = MPU_ACCESS_NOT_BUFFERABLE;

  HAL_MPU_ConfigRegion(&MPU_InitStruct);
  /* Enables the MPU */
  HAL_MPU_Enable(MPU_PRIVILEGED_DEFAULT);

}

void Error_Handler(void)
{
  /* USER CODE BEGIN Error_Handler_Debug */
  /* User can add his own implementation to report the HAL error return state */
  //    __disable_irq();
  while (1)
  {
    led_set(255, 0, 0);

    receive_periodic();
  }
  /* USER CODE END Error_Handler_Debug */
}
